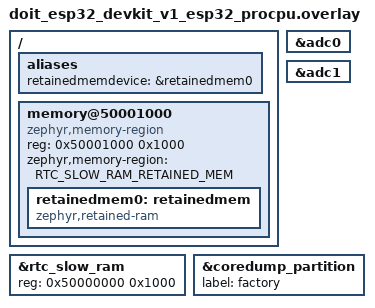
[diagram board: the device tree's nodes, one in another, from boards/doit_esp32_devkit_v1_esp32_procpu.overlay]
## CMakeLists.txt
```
cmake_minimum_required(VERSION 3.16)
set(EXTRA_COMPONENT_DIRS ${CMAKE_CURRENT_LIST_DIR}/components)
include($ENV{IDF_PATH}/tools/cmake/project.cmake)
project(plantmodule)
```

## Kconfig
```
# MoistureController application options (the rest is Zephyr's).
mainmenu "MoistureController firmware"

menu "MoistureController"

config MC_DEV_PROVISION
	bool "Provision from this build (development only)"
	help
	  Stores WiFi, broker and key from the options below on first boot, so the device
	  can run on the bench before BLE pairing (PlantModule/specs.md Part B) exists. The values end
	  up in the firmware image: never use it for devices you hand to someone.

if MC_DEV_PROVISION

config MC_DEV_WIFI_SSID
	string "WiFi network"

config MC_DEV_WIFI_PASSWORD
	string "WiFi password"

config MC_DEV_BROKER_HOST
	string "Gateway LAN address"
	help
	  As shown by `mc-gateway status`, or in the app's gateway screen.

config MC_DEV_BROKER_PORT
	int "Broker port"
	default 8883

config MC_DEV_DEVICE_ID
	string "Device ID"
	help
	  mc-... from the pairing bundle (`mc-api seed-dev` prints one).

config MC_DEV_PSK_HEX
	string "TLS-PSK key (64 hex characters)"

endif # MC_DEV_PROVISION

config MC_DEV_POP_HEX
	string "Development PoP (32 hex characters), used if the factory partition is blank"
	default ""
	help
	  Real devices get their PoP from the factory partition (firmware/tools/make_label.py).
	  For a bench board without one, this lets the pairing window open anyway.

config MC_LOW_TX_POWER
	bool "Low radio transmit power (bench: weak USB supply)"
	help
	  Bluetooth -9 dBm, WiFi 8 dBm instead of the defaults. On a weak USB port or cable the
	  supply dips when the radio transmits, which resets the USB serial chip (or the board).
	  Also fine next to the gateway; it lowers the range.

config MC_WIFI_DIAG
	bool "Scan and log the visible WiFi networks when joining fails"
	help
	  Costs a few seconds per failed cycle: for bring-up, not for the field.

config MC_NTP_SERVER
	string "NTP server"
	default "pool.ntp.org"
	help
	  Needed to check command expiry. Open point: the gateway could serve the time
	  instead, so devices need no internet (Gateway/specs.md Part C §11).

config MC_BATT_ADC_PIN
	int "Battery voltage ADC pin (-1: not measured)"
	default -1
	help
	  Must be an ADC1 pin (32-39) not used by a module slot, wired to the battery through a
	  voltage divider. An unconnected pin floats and reads as a low battery: leave this at -1
	  until the divider is there.

config MC_BATT_DIVIDER_PERCENT
	int "Battery divider factor in percent"
	default 200
	help
	  200 = two equal resistors (the ADC sees half the battery voltage).

endmenu

source "Kconfig.zephyr"
```

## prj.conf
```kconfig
# Moisture controller, DOIT ESP32 DevKit V1.

CONFIG_GPIO=y
CONFIG_ADC=y
CONFIG_JSON_LIBRARY=y
CONFIG_CRC=y
CONFIG_REBOOT=y
CONFIG_HWINFO=y

# Deep sleep between wake cycles; state that must survive lives in RTC slow RAM.
CONFIG_POWEROFF=y
CONFIG_RETAINED_MEM=y

# Settings in the `storage` partition: config, provisioning.
CONFIG_FLASH=y
CONFIG_FLASH_MAP=y
CONFIG_NVS=y
CONFIG_SETTINGS=y
CONFIG_SETTINGS_NVS=y

# WiFi station, DHCP, sockets, SNTP.
CONFIG_NETWORKING=y
CONFIG_WIFI=y
CONFIG_WIFI_ESP32=y
CONFIG_NET_L2_WIFI_MGMT=y
CONFIG_NET_MGMT=y
CONFIG_NET_MGMT_EVENT=y
CONFIG_NET_MGMT_EVENT_INFO=y
CONFIG_NET_MGMT_EVENT_STACK_SIZE=2048
CONFIG_NET_IPV4=y
CONFIG_NET_IPV6=n
CONFIG_NET_UDP=y
CONFIG_NET_TCP=y
CONFIG_NET_DHCPV4=y
CONFIG_NET_SOCKETS=y
CONFIG_DNS_RESOLVER=y
CONFIG_SNTP=y

# MQTT 3.1.1 over TLS 1.2 with a pre-shared key (Gateway/specs.md Part C §2).
CONFIG_MQTT_LIB=y
CONFIG_MQTT_LIB_TLS=y
CONFIG_NET_SOCKETS_SOCKOPT_TLS=y
CONFIG_TLS_CREDENTIALS=y
CONFIG_MBEDTLS=y
# Only this suite: no public-key operations in the handshake, small code (mqtt.md §2).
CONFIG_MBEDTLS_CIPHERSUITE_TLS_PSK_WITH_AES_128_GCM_SHA256=y
CONFIG_MBEDTLS_PSK_MAX_LEN=32

CONFIG_MAIN_STACK_SIZE=8192
CONFIG_LOG=y
CONFIG_LOG_DEFAULT_LEVEL=3

# BLE pairing (PlantModule/specs.md Part B): peripheral with one GATT service; our own secure session
# on top, so no link-layer pairing.
CONFIG_BT=y
CONFIG_BT_PERIPHERAL=y
CONFIG_BT_SMP=n
CONFIG_BT_MAX_CONN=1
CONFIG_BT_DEVICE_NAME_DYNAMIC=y
CONFIG_BT_DEVICE_NAME_MAX=16
CONFIG_BT_L2CAP_TX_MTU=247
CONFIG_BT_BUF_ACL_RX_SIZE=251
CONFIG_BASE64=y
# The session's primitives (src/core/mc_ble.c): X25519, HKDF, HMAC, AES-GCM via PSA Crypto.
CONFIG_PSA_WANT_ALG_ECDH=y
CONFIG_PSA_WANT_ECC_MONTGOMERY_255=y
CONFIG_PSA_WANT_KEY_TYPE_ECC_KEY_PAIR_IMPORT=y
CONFIG_PSA_WANT_KEY_TYPE_ECC_KEY_PAIR_EXPORT=y
CONFIG_PSA_WANT_ALG_HKDF=y
CONFIG_PSA_WANT_ALG_HMAC=y
CONFIG_PSA_WANT_ALG_SHA_256=y
CONFIG_PSA_WANT_ALG_GCM=y
CONFIG_PSA_WANT_KEY_TYPE_AES=y
CONFIG_PSA_WANT_KEY_TYPE_HMAC=y
CONFIG_PSA_WANT_KEY_TYPE_DERIVE=y

# RAM: the ESP32 has 192 KB of static data RAM, and WiFi, Bluetooth and TLS all want some.
# A short-message device with one connection needs far fewer buffers than the defaults.
CONFIG_NET_PKT_RX_COUNT=8
CONFIG_NET_PKT_TX_COUNT=8
CONFIG_NET_BUF_RX_COUNT=20
CONFIG_NET_BUF_TX_COUNT=20
CONFIG_ESP32_WIFI_STATIC_RX_BUFFER_NUM=6
CONFIG_BT_BUF_ACL_TX_COUNT=10
CONFIG_BT_L2CAP_TX_BUF_COUNT=10

# Heap: drivers alone ask for 81 KB (WiFi 51, Bluetooth 26) assuming 32 + 32 dynamic WiFi
# buffers. Tiny messages need a fraction: fewer buffers, small TLS records (the default
# 16 KB in + 16 KB out would not fit next to the radios), and a heap sized by hand.
# Run `hal_heap_log()` (logged at each step of a cycle) on the board before tightening more.
CONFIG_ESP32_WIFI_DYNAMIC_TX_BUFFER_NUM=8
CONFIG_ESP32_WIFI_DYNAMIC_RX_BUFFER_NUM=8
CONFIG_MBEDTLS_SSL_IN_CONTENT_LEN=2048
CONFIG_MBEDTLS_SSL_OUT_CONTENT_LEN=2048
CONFIG_HEAP_MEM_POOL_IGNORE_MIN=y
CONFIG_HEAP_MEM_POOL_SIZE=44000
# mbedTLS would otherwise malloc from the libc arena, which is ~1 kB here (RAM goes to the heaps
# above): the TLS handshake failed with -ENOMEM. Its own heap, taken from the system heap's share.
CONFIG_MBEDTLS_ENABLE_HEAP=y
CONFIG_MBEDTLS_HEAP_SIZE=16384
CONFIG_SYS_HEAP_RUNTIME_STATS=y

# An unattended device must not stand still after a crash: restart (and pump pins come up off).
CONFIG_RESET_ON_FATAL_ERROR=y
```

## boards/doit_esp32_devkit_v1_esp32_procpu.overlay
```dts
/*
 * Moisture controller on the DOIT ESP32 DevKit V1.
 *
 * Module pins are NOT fixed here: they come from the config and are bound at runtime
 * (PlantModule/specs.md Part A "Module system"). The overlay only enables what they need.
 */

/ {
	aliases {
		retainedmemdevice = &retainedmem0;
	};

	/* 4 KB of RTC slow RAM keep the cycle state through deep sleep (src/core/mc_rtc.h). */
	memory@50001000 {
		compatible = "zephyr,memory-region", "mmio-sram";
		reg = <0x50001000 0x1000>;
		zephyr,memory-region = "RTC_SLOW_RAM_RETAINED_MEM";
		status = "okay";

		retainedmem0: retainedmem {
			compatible = "zephyr,retained-ram";
			status = "okay";
		};
	};
};

&rtc_slow_ram {
	/* 8 KB minus the retained 4 KB */
	reg = <0x50000000 0x1000>;
};

/* ADC1 (GPIO 32-39) and ADC2 (GPIO 4, 12-15, 25-27): channels are set up at runtime. */
&adc0 {
	status = "okay";
};

&adc1 {
	status = "okay";
};

/*
 * The last 4 KB of flash hold the factory page with the pairing PoP (ble.md §7.7). The board
 * reserves them for core dumps, which this firmware does not use. They are outside the
 * settings partition, so a factory reset never touches them.
 */
&coredump_partition {
	label = "factory";
};
```

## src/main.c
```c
/*
 * Moisture controller: wake, run one cycle (src/core/mc_cycle.c), sleep.
 * PlantModule/specs.md Part A has the design; Gateway/specs.md Part C the wire protocol, PlantModule/specs.md Part B pairing.
 */
#include <zephyr/kernel.h>
#include <zephyr/logging/log.h>
#include <zephyr/sys/reboot.h>

#include "hal.h"

LOG_MODULE_REGISTER(main, LOG_LEVEL_INF);

/* Not paired: look for the app again after this (ble.md §3: the window reopens on every wake). */
#define UNPROVISIONED_SLEEP_S 1800
#define PAIRING_WINDOW_S 600     /* unprovisioned */
#define MAINTENANCE_WINDOW_S 300 /* after a 3 s BOOT press */
#define MAINTENANCE_SERVICE_S (15 * 60)

static struct mc_rtc rtc;
static struct mc_app app;
static struct hal_prov prov;

/* BOOT held 10 s: wipe pairing and config (the PoP stays), start over unpaired. */
static void factory_reset(void)
{
	LOG_WRN("factory reset");
	hal_store_factory_reset();
	hal_rtc_clear();
	k_msleep(200);
	sys_reboot(SYS_REBOOT_COLD);
}

/* Opens the pairing window; returns true if the device was paired (and must restart). */
static bool pairing_window(int32_t seconds)
{
	uint8_t pop[MC_BLE_POP_LEN];

	if (!hal_store_load_pop(pop)) {
		LOG_ERR("no PoP in the factory partition: pairing is not possible (tools/make_label.py)");
		return false;
	}
	if (hal_ble_init() != 0) {
		return false;
	}
	enum hal_ble_result r = hal_ble_pairing_window(pop, seconds);

	LOG_INF("pairing window closed: %s", r == HAL_BLE_PAIRED ? "paired" :
					      r == HAL_BLE_LOCKED ? "too many failed attempts" :
					      r == HAL_BLE_TIMEOUT ? "timeout" : "error");
	return r == HAL_BLE_PAIRED;
}

int main(void)
{
	hal_board_init();
	hal_heap_log("at boot");
	hal_store_init();
	hal_rtc_load(&rtc);

	enum mc_wake wake = hal_wake_cause(&rtc);

	LOG_INF("firmware " MC_FW_VERSION ", wake: %s", mc_wake_name(wake));

	/* BOOT button: 3 s opens the pairing window, 10 s is a factory reset (ble.md §3) */
	int32_t held = 0;

	if (wake == MC_WAKE_BUTTON) {
		held = hal_board_button_hold_ms(HAL_HOLD_FACTORY_RESET_MS);
		if (held >= HAL_HOLD_FACTORY_RESET_MS) {
			factory_reset();
		}
	}
	bool maintenance = held >= HAL_HOLD_MAINTENANCE_MS;

	hal_button_start(factory_reset); /* from here on a 10 s hold resets, whatever the device does */

	LOG_INF("loading pairing data");
	bool paired = hal_store_load_prov(&prov);

	if (!paired || maintenance) {
		if (pairing_window(paired ? MAINTENANCE_WINDOW_S : PAIRING_WINDOW_S)) {
			k_msleep(500);
			sys_reboot(SYS_REBOOT_COLD);
		}
		if (!paired) {
			LOG_WRN("not paired: sleeping %d s", UNPROVISIONED_SLEEP_S);
			hal_sleep(UNPROVISIONED_SLEEP_S);
		}
	}
	hal_net_set_prov(&prov);
	LOG_INF("paired as %s, gateway %s:%u", prov.device_id, prov.host, prov.port);

	enum mc_cfg_load loaded = hal_store_load_config(&app.cfg);

	LOG_INF("config: %s (rev %d, %d slots)",
		loaded == MC_CFG_LOADED ? "loaded" : loaded == MC_CFG_MISSING ? "none yet" : "CORRUPT",
		app.cfg.rev, app.cfg.n);

	app.continuing = false;
	while (true) {
		int64_t cycle_started = k_uptime_get();

		mc_app_begin(&app, &rtc, &hal_io, NULL, wake, loaded);
		if (!app.continuing) {
			/* A button press keeps the device up for at least BUTTON_AWAKE_MIN_S (or awake_s). */
			if (maintenance) {
				app.service_request_s = MAINTENANCE_SERVICE_S;
			} else if (wake == MC_WAKE_BUTTON) {
				app.service_request_s = MAX(MC_BUTTON_AWAKE_MIN_S, app.cfg.awake_s);
			}
			if (wake == MC_WAKE_BUTTON) {
				app.min_awake_s = MC_BUTTON_AWAKE_MIN_S;
			}
		}
		mc_cycle(&app);
		hal_rtc_store(&rtc);
		LOG_INF("cycle done, next wake in %d s", app.next_wake_s);

		if (app.reboot) {
			LOG_INF("rebooting as commanded");
			sys_reboot(SYS_REBOOT_COLD);
		}
		if (app.next_wake_s > 0) {
			break;
		}
		/* wake_interval_s = 0: never deep-sleep, start the next cycle (no more often than one a minute) */
		int64_t used = k_uptime_get() - cycle_started;

		if (used < MC_AWAKE_CYCLE_S * 1000) {
			k_msleep(MC_AWAKE_CYCLE_S * 1000 - (int32_t)used);
		}
		app.continuing = true;
		app.service_request_s = 0;
		app.min_awake_s = 0;
		wake = MC_WAKE_TIMER;
		loaded = MC_CFG_LOADED;
	}
	hal_sleep(app.next_wake_s);
	return 0;
}
```
